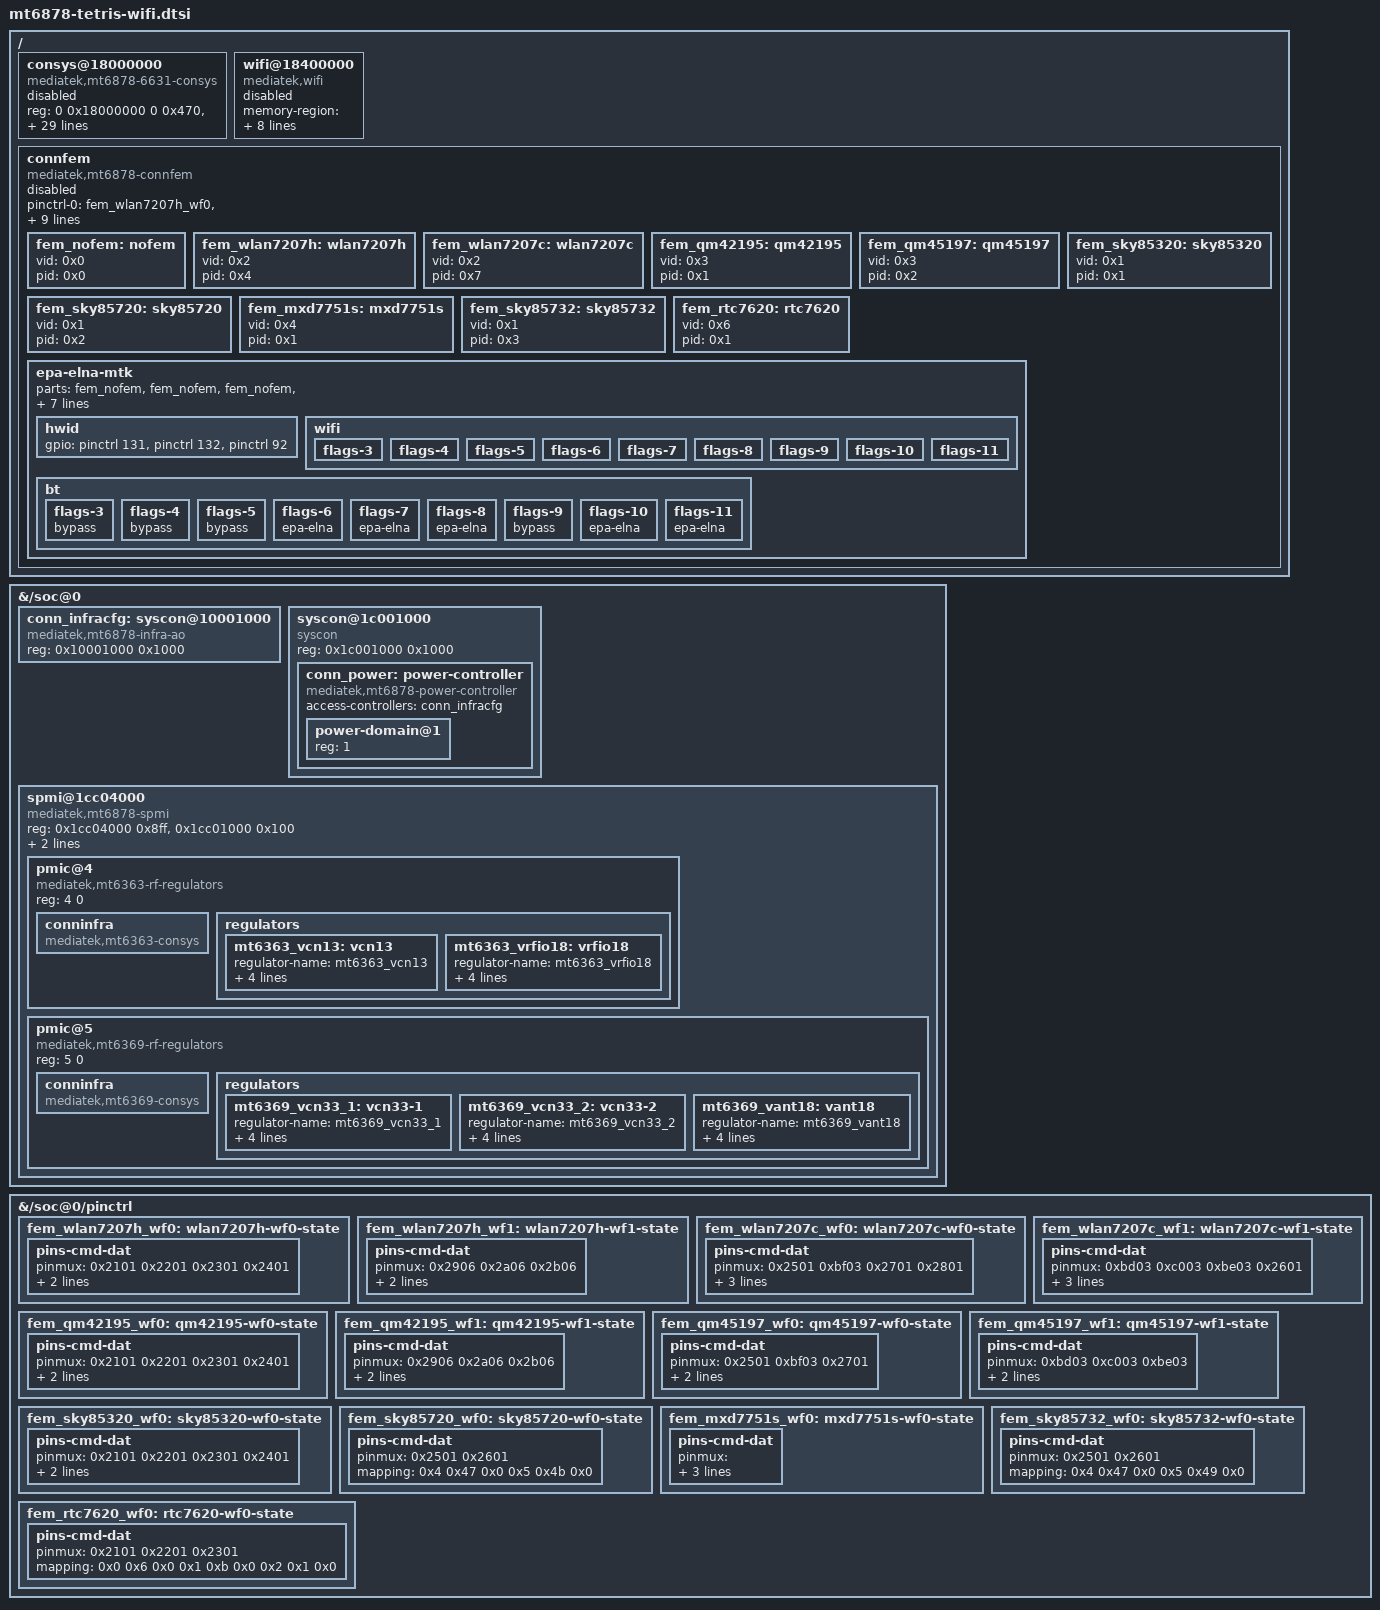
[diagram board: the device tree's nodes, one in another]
/* SPDX-License-Identifier: (GPL-2.0-only OR BSD-2-Clause) */
/* Apply after the v9 board tree. The radio consumers are staged disabled. */

&{/soc@0} {
	conn_infracfg: syscon@10001000 {
		compatible = "mediatek,mt6878-infra-ao", "syscon";
		reg = <0x10001000 0x1000>;
	};

	syscon@1c001000 {
		compatible = "syscon", "simple-mfd";
		reg = <0x1c001000 0x1000>;

		conn_power: power-controller {
			compatible = "mediatek,mt6878-power-controller";
			access-controllers = <&conn_infracfg>;
			#address-cells = <1>;
			#size-cells = <0>;
			#power-domain-cells = <1>;

			power-domain@1 {
				reg = <1>;
				#power-domain-cells = <0>;
			};
		};
	};

	spmi@1cc04000 {
		compatible = "mediatek,mt6878-spmi";
		reg = <0x1cc04000 0x8ff>, <0x1cc01000 0x100>;
		reg-names = "pmif", "spmimst";
		interrupts-extended = <&{/soc@0/pinctrl} 212 4>;
		interrupt-names = "rcs";
		interrupt-controller;
		#interrupt-cells = <3>;
		#address-cells = <2>;
		#size-cells = <0>;

		pmic@4 {
			compatible = "mediatek,mt6363-rf-regulators";
			reg = <4 0>;

			conninfra {
				compatible = "mediatek,mt6363-consys";
			};

			regulators {
				mt6363_vcn13: vcn13 {
					regulator-name = "mt6363_vcn13";
					regulator-min-microvolt = <900000>;
					regulator-max-microvolt = <1810000>;
					regulator-enable-ramp-delay = <180>;
					regulator-allowed-modes = <0 2>;
				};

				mt6363_vrfio18: vrfio18 {
					regulator-name = "mt6363_vrfio18";
					regulator-min-microvolt = <600000>;
					regulator-max-microvolt = <2100000>;
					regulator-enable-ramp-delay = <180>;
					regulator-allowed-modes = <0 2>;
				};
			};
		};

		pmic@5 {
			compatible = "mediatek,mt6369-rf-regulators";
			reg = <5 0>;

			conninfra {
				compatible = "mediatek,mt6369-consys";
			};

			regulators {
				mt6369_vcn33_1: vcn33-1 {
					regulator-name = "mt6369_vcn33_1";
					regulator-min-microvolt = <1200000>;
					regulator-max-microvolt = <3500000>;
					regulator-enable-ramp-delay = <680>;
					regulator-allowed-modes = <0 2>;
				};

				mt6369_vcn33_2: vcn33-2 {
					regulator-name = "mt6369_vcn33_2";
					regulator-min-microvolt = <1200000>;
					regulator-max-microvolt = <3500000>;
					regulator-enable-ramp-delay = <680>;
					regulator-allowed-modes = <0 2>;
				};

				mt6369_vant18: vant18 {
					regulator-name = "mt6369_vant18";
					regulator-min-microvolt = <600000>;
					regulator-max-microvolt = <2100000>;
					regulator-enable-ramp-delay = <680>;
					regulator-allowed-modes = <0 2>;
				};
			};
		};
	};
};

/ {
	consys@18000000 {
		compatible = "mediatek,mt6878-6631-consys";
		#thermal-sensor-cells = <0>;
		reg = <0 0x18000000 0 0x470>, <0 0x10001000 0 0xee4>,
		      <0 0x10005000 0 0xa7c>, <0 0x11ec0000 0 0xa04>,
		      <0 0x18001000 0 0x658>, <0 0x18003000 0 0x204>,
		      <0 0x1800e000 0 0x118>, <0 0x18011000 0 0x138>,
		      <0 0x18012000 0 0x98>, <0 0x18020000 0 0x4c>,
		      <0 0x18023000 0 0xe28>, <0 0x1803b000 0 0x18>,
		      <0 0x18040000 0 0x2c>, <0 0x18041000 0 0x140>,
		      <0 0x18042000 0 0x324>, <0 0x18046000 0 0x324>,
		      <0 0x1804b000 0 0x414>, <0 0x1804d000 0 0x41c>,
		      <0 0x1804f000 0 0x148>, <0 0x18053800 0 0x1000>,
		      <0 0x18060000 0 0xbf8>, <0 0x18070000 0 0x8004>,
		      <0 0x1c001000 0 0xfd0>, <0 0x1c00a000 0 0x51c>,
		      <0 0x1803c000 0 0x34>, <0 0x1803e000 0 0x34>;
		power-domains = <&conn_power 1>;
		mt6363_vcn13-supply = <&mt6363_vcn13>;
		mt6363_vrfio18-supply = <&mt6363_vrfio18>;
		mt6369_vcn33_1-supply = <&mt6369_vcn33_1>;
		mt6369_vcn33_2-supply = <&mt6369_vcn33_2>;
		mt6369_vant18-supply = <&mt6369_vant18>;
		emi-addr = <0 0x85e00000>;
		emi-size = <0xc00000>;
		ro-bt-emi-size = <0x2e0000>;
		ro-gps-emi-size = <0xa0000>;
		ro-wifi-emi-size = <0x300000>;
		ro-emi-size = <0x680000>;
		rw-emi-size = <0x480000>;
		emi-alignment = <0x100000>;
		emi-max-addr = <0x90000000>;
		adie-sku = <0 1>;
		status = "disabled";
	};

	wifi@18400000 {
		compatible = "mediatek,wifi";
		memory-region = <&{/reserved-memory/mblock-42-shared-dma-pool_wifi-reserve-memory_dma}>;
		remap-idx = <1>;
		reg = <0 0x18400000 0 0>, <0 0x18000000 0 0x700000>;
		interrupts = <0 0x1e4 4 0>, <0 0x2b4 4 0>;
		emi-addr = <0>;
		emi-size = <0x1400000>;
		emi-alignment = <0x1000000>;
		emi-max-addr = <0xc0000000>;
		status = "disabled";
	};
};

&{/soc@0/pinctrl} {
	fem_wlan7207h_wf0: wlan7207h-wf0-state {
		pins-cmd-dat {
			pinmux = <0x2101 0x2201 0x2301 0x2401>;
			mapping = <0x0 0x3 0x0 0x1 0x2 0x0 0x2 0x4 0x0>,
			          <0x3 0xb 0x0>;
		};
	};
	fem_wlan7207h_wf1: wlan7207h-wf1-state {
		pins-cmd-dat {
			pinmux = <0x2906 0x2a06 0x2b06>;
			mapping = <0x8 0x83 0x0 0x9 0x82 0x0 0xa 0x84 0x0>;
		};
	};
	fem_wlan7207c_wf0: wlan7207c-wf0-state {
		pins-cmd-dat {
			pinmux = <0x2501 0xbf03 0x2701 0x2801>;
			mapping = <0x4 0x4a 0x0 0x14 0x4b 0x0 0x6 0x4c 0x0>,
			          <0x7 0x41 0x0>;
		};
	};
	fem_wlan7207c_wf1: wlan7207c-wf1-state {
		pins-cmd-dat {
			pinmux = <0xbd03 0xc003 0xbe03 0x2601>;
			mapping = <0x12 0xca 0x0 0x15 0xcb 0x0 0x13 0xcc 0x0>,
			          <0x5 0xc1 0x0>;
		};
	};
	fem_qm42195_wf0: qm42195-wf0-state {
		pins-cmd-dat {
			pinmux = <0x2101 0x2201 0x2301 0x2401>;
			mapping = <0x0 0x3 0x0 0x1 0x2 0x0 0x2 0x4 0x0>,
			          <0x3 0xb 0x0>;
		};
	};
	fem_qm42195_wf1: qm42195-wf1-state {
		pins-cmd-dat {
			pinmux = <0x2906 0x2a06 0x2b06>;
			mapping = <0x8 0x83 0x0 0x9 0x82 0x0 0xa 0x84 0x0>;
		};
	};
	fem_qm45197_wf0: qm45197-wf0-state {
		pins-cmd-dat {
			pinmux = <0x2501 0xbf03 0x2701>;
			mapping = <0x4 0x4a 0x0 0x14 0x4b 0x0 0x6 0x4c 0x0>;
		};
	};
	fem_qm45197_wf1: qm45197-wf1-state {
		pins-cmd-dat {
			pinmux = <0xbd03 0xc003 0xbe03>;
			mapping = <0x12 0xca 0x0 0x15 0xcb 0x0 0x13 0xcc 0x0>;
		};
	};
	fem_sky85320_wf0: sky85320-wf0-state {
		pins-cmd-dat {
			pinmux = <0x2101 0x2201 0x2301 0x2401>;
			mapping = <0x0 0xc 0x0 0x1 0xd 0x0 0x2 0x2 0x0>,
			          <0x3 0xb 0x0>;
		};
	};
	fem_sky85720_wf0: sky85720-wf0-state {
		pins-cmd-dat {
			pinmux = <0x2501 0x2601>;
			mapping = <0x4 0x47 0x0 0x5 0x4b 0x0>;
		};
	};
	fem_mxd7751s_wf0: mxd7751s-wf0-state {
		pins-cmd-dat {
			pinmux = <0x2201 0x2301 0x2401 0x2501 0x2601 0x2701>;
			mapping = <0x1 0xb 0x0 0x2 0xd 0x0 0x3 0xc 0x0>,
			          <0x4 0x42 0x0 0x5 0x45 0x0 0x6 0x10 0x0>;
		};
	};
	fem_sky85732_wf0: sky85732-wf0-state {
		pins-cmd-dat {
			pinmux = <0x2501 0x2601>;
			mapping = <0x4 0x47 0x0 0x5 0x49 0x0>;
		};
	};
	fem_rtc7620_wf0: rtc7620-wf0-state {
		pins-cmd-dat {
			pinmux = <0x2101 0x2201 0x2301>;
			mapping = <0x0 0x6 0x0 0x1 0xb 0x0 0x2 0x1 0x0>;
		};
	};
};

/ {
	connfem {
		compatible = "mediatek,mt6878-connfem";
		status = "disabled";
		pinctrl-names = "wlan7207h-wlan7207c",
			        "qm42195-qm45197",
			        "sky85320-sky85720",
			        "mxd7751s-mxd7751s",
			        "nofem-sky85732",
			        "nofem-qm45197",
			        "rtc7620-nofem";
		pinctrl-0 = <&fem_wlan7207h_wf0 &fem_wlan7207h_wf1 &fem_wlan7207c_wf0 &fem_wlan7207c_wf1>;
		pinctrl-1 = <&fem_qm42195_wf0 &fem_qm42195_wf1 &fem_qm45197_wf0 &fem_qm45197_wf1>;
		pinctrl-2 = <&fem_sky85320_wf0 &fem_sky85720_wf0>;
		pinctrl-3 = <&fem_mxd7751s_wf0>;
		pinctrl-4 = <&fem_sky85732_wf0>;
		pinctrl-5 = <&fem_qm45197_wf0 &fem_qm45197_wf1>;
		pinctrl-6 = <&fem_rtc7620_wf0>;

		fem_nofem: nofem {
			vid = <0x0>;
			pid = <0x0>;
		};

		fem_wlan7207h: wlan7207h {
			vid = <0x2>;
			pid = <0x4>;
		};

		fem_wlan7207c: wlan7207c {
			vid = <0x2>;
			pid = <0x7>;
		};

		fem_qm42195: qm42195 {
			vid = <0x3>;
			pid = <0x1>;
		};

		fem_qm45197: qm45197 {
			vid = <0x3>;
			pid = <0x2>;
		};

		fem_sky85320: sky85320 {
			vid = <0x1>;
			pid = <0x1>;
		};

		fem_sky85720: sky85720 {
			vid = <0x1>;
			pid = <0x2>;
		};

		fem_mxd7751s: mxd7751s {
			vid = <0x4>;
			pid = <0x1>;
		};

		fem_sky85732: sky85732 {
			vid = <0x1>;
			pid = <0x3>;
		};

		fem_rtc7620: rtc7620 {
			vid = <0x6>;
			pid = <0x1>;
		};

		epa-elna-mtk {
			parts = <&fem_nofem &fem_nofem &fem_nofem &fem_nofem
				 &fem_nofem &fem_nofem &fem_mxd7751s &fem_mxd7751s
				 &fem_sky85320 &fem_sky85720 &fem_sky85320 &fem_sky85720
				 &fem_qm42195 &fem_qm45197 &fem_wlan7207h &fem_wlan7207c
				 &fem_nofem &fem_sky85732 &fem_nofem &fem_sky85732
				 &fem_nofem &fem_qm45197 &fem_rtc7620 &fem_nofem>;

			hwid {
				gpio = <&{/soc@0/pinctrl} 131 0>,
				       <&{/soc@0/pinctrl} 132 0>,
				       <&{/soc@0/pinctrl} 92 0>;
			};

			wifi {
				flags-3 {
				};
				flags-4 {
				};
				flags-5 {
				};
				flags-6 {
				};
				flags-7 {
				};
				flags-8 {
				};
				flags-9 {
				};
				flags-10 {
				};
				flags-11 {
				};
			};

			bt {
				flags-3 {
					bypass;
				};
				flags-4 {
					bypass;
				};
				flags-5 {
					bypass;
				};
				flags-6 {
					epa-elna;
				};
				flags-7 {
					epa-elna;
				};
				flags-8 {
					epa-elna;
				};
				flags-9 {
					bypass;
				};
				flags-10 {
					epa-elna;
				};
				flags-11 {
					epa-elna;
				};
			};
		};
	};
};
